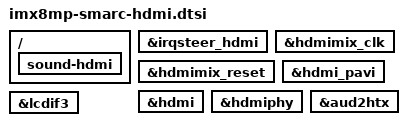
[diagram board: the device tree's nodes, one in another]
// SPDX-License-Identifier: (GPL-2.0+ OR MIT)
/*
 * Copyright 2021 Embedian, Inc.
 */

/ {
	sound-hdmi {
		status = "okay";
	};
};

&irqsteer_hdmi {
	status = "okay";
};

&hdmimix_clk {
	status = "okay";
};

&hdmimix_reset {
	status = "okay";
};

&hdmi_pavi {
	status = "okay";
};

&hdmi {
	status = "okay";
};

&hdmiphy {
	status = "okay";
};

&aud2htx {
	status = "okay";
};

&lcdif3 {
	status = "okay";
};
